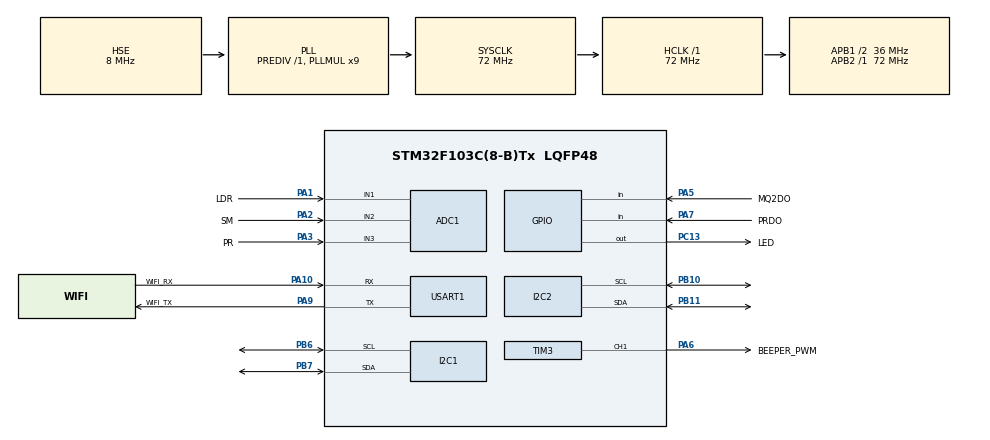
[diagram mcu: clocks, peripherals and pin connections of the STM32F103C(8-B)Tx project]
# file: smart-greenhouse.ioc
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ADC1.Channel-4\#ChannelRegularConversion=ADC_CHANNEL_1
ADC1.NbrOfConversionFlag=1
ADC1.Rank-4\#ChannelRegularConversion=1
ADC1.SamplingTime-4\#ChannelRegularConversion=ADC_SAMPLETIME_1CYCLE_5
ADC1.master=1
Mcu.Family=STM32F1
Mcu.Name=STM32F103C(8-B)Tx
Mcu.Package=LQFP48
NVIC.ADC1_2_IRQn=true\:0\:0\:false\:false\:true\:true\:true\:true
NVIC.I2C1_ER_IRQn=true\:0\:0\:false\:false\:true\:true\:true\:true
NVIC.I2C1_EV_IRQn=true\:0\:0\:false\:false\:true\:true\:true\:true
NVIC.I2C2_ER_IRQn=true\:0\:0\:false\:false\:true\:true\:true\:true
NVIC.I2C2_EV_IRQn=true\:0\:0\:false\:false\:true\:true\:true\:true
NVIC.PriorityGroup=NVIC_PRIORITYGROUP_4
NVIC.RCC_IRQn=true\:0\:0\:false\:false\:true\:true\:false\:true
NVIC.TIM3_IRQn=true\:0\:0\:false\:false\:true\:true\:true\:true
NVIC.USART1_IRQn=true\:0\:0\:false\:false\:true\:true\:true\:true
PA1.GPIO_Label=LDR
PA1.Signal=ADCx_IN1
PA10.GPIO_Label=WIFI_RX
PA10.Mode=Asynchronous
PA10.Signal=USART1_RX
PA13.Mode=Serial_Wire
PA13.Signal=SYS_JTMS-SWDIO
PA14.Mode=Serial_Wire
PA14.Signal=SYS_JTCK-SWCLK
PA2.GPIO_Label=SM
PA2.Signal=ADCx_IN2
PA3.GPIO_Label=PR
PA3.Signal=ADCx_IN3
PA5.GPIO_Label=MQ2DO
PA5.Signal=GPIO_Input
PA6.GPIO_Label=BEEPER_PWM
PA6.Signal=S_TIM3_CH1
PA7.GPIO_Label=PRDO
PA7.Signal=GPIO_Input
PA9.GPIO_Label=WIFI_TX
PA9.Mode=Asynchronous
PA9.Signal=USART1_TX
PB10.Mode=I2C
PB10.Signal=I2C2_SCL
PB11.Mode=I2C
PB11.Signal=I2C2_SDA
PB6.Mode=I2C
PB6.Signal=I2C1_SCL
PB7.Mode=I2C
PB7.Signal=I2C1_SDA
PC13-TAMPER-RTC.GPIO_Label=LED
PC13-TAMPER-RTC.Signal=GPIO_Output
PD0-OSC_IN.Mode=HSE-External-Oscillator
PD0-OSC_IN.Signal=RCC_OSC_IN
PD1-OSC_OUT.Mode=HSE-External-Oscillator
PD1-OSC_OUT.Signal=RCC_OSC_OUT
ProjectManager.HeapSize=0x200
ProjectManager.StackSize=0x400
ProjectManager.TargetToolchain=Makefile
RCC.AHBFreq_Value=72000000
RCC.APB1CLKDivider=RCC_HCLK_DIV2
RCC.APB1Freq_Value=36000000
RCC.APB1TimFreq_Value=72000000
RCC.APB2Freq_Value=72000000
RCC.APB2TimFreq_Value=72000000
RCC.HCLKFreq_Value=72000000
RCC.PLLMUL=RCC_PLL_MUL9
RCC.PLLSourceVirtual=RCC_PLLSOURCE_HSE
RCC.SYSCLKFreq_VALUE=72000000
RCC.SYSCLKSource=RCC_SYSCLKSOURCE_PLLCLK
RCC.USBFreq_Value=72000000
SH.ADCx_IN1.0=ADC1_IN1,IN1
SH.ADCx_IN2.0=ADC1_IN2,IN2
SH.ADCx_IN3.0=ADC1_IN3,IN3
SH.S_TIM3_CH1.0=TIM3_CH1,PWM Generation1 CH1
TIM3.Channel-PWM\ Generation1\ CH1=TIM_CHANNEL_1
TIM3.Period=249
TIM3.Prescaler=71
USART1.VirtualMode=VM_ASYNC
board=custom

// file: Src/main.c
/* USER CODE BEGIN Header */
/**
 ******************************************************************************
 * @file           : main.c
 * @brief          : Main program body
 ******************************************************************************
 * @attention
 *
 * Copyright (c) 2024 STMicroelectronics.
 * All rights reserved.
 *
 * This software is licensed under terms that can be found in the LICENSE file
 * in the root directory of this software component.
 * If no LICENSE file comes with this software, it is provided AS-IS.
 *
 ******************************************************************************
 */
/* USER CODE END Header */
#include "main.h"
#include "adc.h"
#include "gpio.h"
#include "i2c.h"
#include "tim.h"
#include "usart.h"

/* USER CODE BEGIN Includes */

#include "start.hh"

/* USER CODE END Includes */

void SystemClock_Config(void);

int main(void) {

  /* MCU Configuration--------------------------------------------------------*/

  /* Reset of all peripherals, Initializes the Flash interface and the Systick.
   */
  HAL_Init();

  /* Configure the system clock */
  SystemClock_Config();

  /* Initialize all configured peripherals */
  MX_GPIO_Init();
  MX_I2C1_Init();
  MX_I2C2_Init();
  MX_TIM3_Init();
  MX_ADC1_Init();
  MX_USART1_UART_Init();
  /* USER CODE BEGIN 2 */

  start();

  /* USER CODE END 2 */

  /* Infinite loop */
  while (1) {

  }
}

void SystemClock_Config(void) {
  RCC_OscInitTypeDef RCC_OscInitStruct = {0};
  RCC_ClkInitTypeDef RCC_ClkInitStruct = {0};
  RCC_PeriphCLKInitTypeDef PeriphClkInit = {0};

  /** Initializes the RCC Oscillators according to the specified parameters
   * in the RCC_OscInitTypeDef structure.
   */
  RCC_OscInitStruct.OscillatorType = RCC_OSCILLATORTYPE_HSE;
  RCC_OscInitStruct.HSEState = RCC_HSE_ON;
  RCC_OscInitStruct.HSEPredivValue = RCC_HSE_PREDIV_DIV1;
  RCC_OscInitStruct.HSIState = RCC_HSI_ON;
  RCC_OscInitStruct.PLL.PLLState = RCC_PLL_ON;
  RCC_OscInitStruct.PLL.PLLSource = RCC_PLLSOURCE_HSE;
  RCC_OscInitStruct.PLL.PLLMUL = RCC_PLL_MUL9;
  if (HAL_RCC_OscConfig(&RCC_OscInitStruct) != HAL_OK) {
    Error_Handler();
  }

  /** Initializes the CPU, AHB and APB buses clocks
   */
  RCC_ClkInitStruct.ClockType = RCC_CLOCKTYPE_HCLK | RCC_CLOCKTYPE_SYSCLK |
                                RCC_CLOCKTYPE_PCLK1 | RCC_CLOCKTYPE_PCLK2;
  RCC_ClkInitStruct.SYSCLKSource = RCC_SYSCLKSOURCE_PLLCLK;
  RCC_ClkInitStruct.AHBCLKDivider = RCC_SYSCLK_DIV1;
  RCC_ClkInitStruct.APB1CLKDivider = RCC_HCLK_DIV2;
  RCC_ClkInitStruct.APB2CLKDivider = RCC_HCLK_DIV1;

  if (HAL_RCC_ClockConfig(&RCC_ClkInitStruct, FLASH_LATENCY_2) != HAL_OK) {
    Error_Handler();
  }
  PeriphClkInit.PeriphClockSelection = RCC_PERIPHCLK_ADC;
  PeriphClkInit.AdcClockSelection = RCC_ADCPCLK2_DIV2;
  if (HAL_RCCEx_PeriphCLKConfig(&PeriphClkInit) != HAL_OK) {
    Error_Handler();
  }
}

void Error_Handler(void) {
  __disable_irq();
  while (1) {
  }
}

#ifdef USE_FULL_ASSERT
/**
 * @brief  Reports the name of the source file and the source line number
 *         where the assert_param error has occurred.
 * @param  file: pointer to the source file name
 * @param  line: assert_param error line source number
 * @retval None
 */
void assert_failed(uint8_t *file, uint32_t line) {
  /* USER CODE BEGIN 6 */
  /* User can add his own implementation to report the file name and line
     number, ex: printf("Wrong parameters value: file %s on line %d\r\n", file,
     line) */
  /* USER CODE END 6 */
}
#endif /* USE_FULL_ASSERT */
